# BL602 register map
Vendor: bouffalolab; Series: WiFi BT
Registers are 32-bit, read-write, reset 0x0 unless marked. A register's access mark holds for its fields unless they carry their own. Offsets are from the block's base; [hi:lo] are bit positions.

## CCI
Base 0x40008000
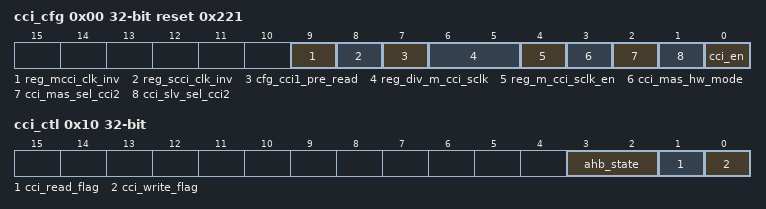
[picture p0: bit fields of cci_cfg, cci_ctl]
0x00 cci_cfg reset 0x221
  [9] reg_mcci_clk_inv, [8] reg_scci_clk_inv, [7] cfg_cci1_pre_read, [6:5] reg_div_m_cci_sclk, [4] reg_m_cci_sclk_en, [3] cci_mas_hw_mode, [2] cci_mas_sel_cci2, [1] cci_slv_sel_cci2, [0] cci_en
0x04 cci_addr
  [31:0] apb_cci_addr
0x08 cci_wdata
  [31:0] apb_cci_wdata
0x0C cci_rdata
  [31:0] apb_cci_rdata ro
0x10 cci_ctl
  [3:2] ahb_state ro, [1] cci_read_flag ro, [0] cci_write_flag ro

## L1C — Cache control
Base 0x40009000
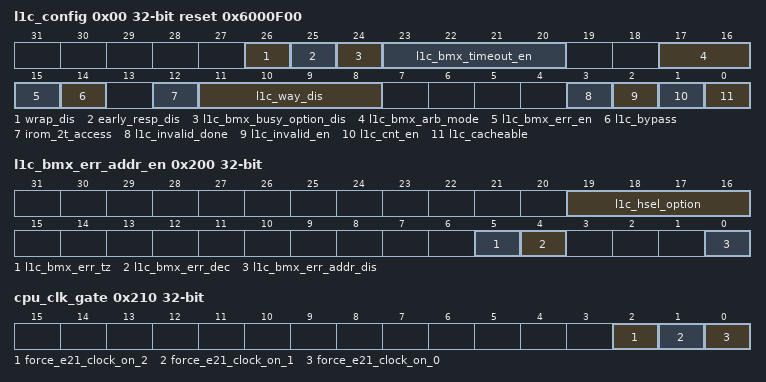
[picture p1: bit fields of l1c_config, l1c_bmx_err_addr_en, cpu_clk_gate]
0x00 l1c_config reset 0x6000F00
  [26] wrap_dis, [25] early_resp_dis, [24] l1c_bmx_busy_option_dis, [23:20] l1c_bmx_timeout_en, [17:16] l1c_bmx_arb_mode, [15] l1c_bmx_err_en, [14] l1c_bypass, [12] irom_2t_access, [11:8] l1c_way_dis, [3] l1c_invalid_done ro, [2] l1c_invalid_en, [1] l1c_cnt_en, [0] l1c_cacheable
0x04 hit_cnt_lsb ro
0x08 hit_cnt_msb ro
0x0C miss_cnt ro
0x10 l1c_range
0x200 l1c_bmx_err_addr_en
  [19:16] l1c_hsel_option, [5] l1c_bmx_err_tz ro, [4] l1c_bmx_err_dec ro, [0] l1c_bmx_err_addr_dis
0x204 l1c_bmx_err_addr ro
0x208 irom1_misr_dataout_0 ro
0x20C irom1_misr_dataout_1
0x210 cpu_clk_gate
  [2] force_e21_clock_on_2, [1] force_e21_clock_on_1, [0] force_e21_clock_on_0

## UART — UART control
Base 0x4000A000
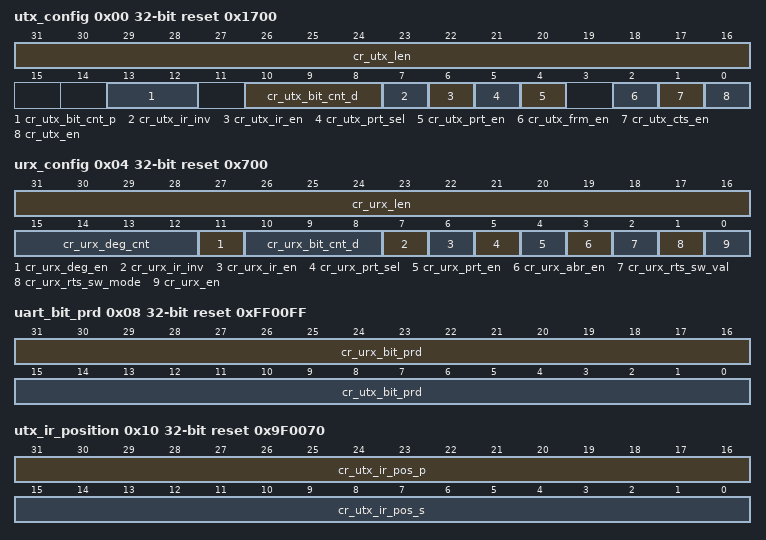
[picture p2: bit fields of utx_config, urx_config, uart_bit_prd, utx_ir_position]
0x00 utx_config reset 0x1700
  [31:16] cr_utx_len, [13:12] cr_utx_bit_cnt_p, [10:8] cr_utx_bit_cnt_d, [7] cr_utx_ir_inv, [6] cr_utx_ir_en, [5] cr_utx_prt_sel, [4] cr_utx_prt_en, [2] cr_utx_frm_en, [1] cr_utx_cts_en, [0] cr_utx_en
0x04 urx_config reset 0x700
  [31:16] cr_urx_len, [15:12] cr_urx_deg_cnt, [11] cr_urx_deg_en, [10:8] cr_urx_bit_cnt_d, [7] cr_urx_ir_inv, [6] cr_urx_ir_en, [5] cr_urx_prt_sel, [4] cr_urx_prt_en, [3] cr_urx_abr_en, [2] cr_urx_rts_sw_val, [1] cr_urx_rts_sw_mode, [0] cr_urx_en
0x08 uart_bit_prd reset 0xFF00FF
  [31:16] cr_urx_bit_prd, [15:0] cr_utx_bit_prd
0x0C data_config
  [0] cr_uart_bit_inv
0x10 utx_ir_position reset 0x9F0070
  [31:16] cr_utx_ir_pos_p, [15:0] cr_utx_ir_pos_s
0x14 urx_ir_position reset 0x6F
  [15:0] cr_urx_ir_pos_s
0x18 urx_rto_timer reset 0xF
  [7:0] cr_urx_rto_value
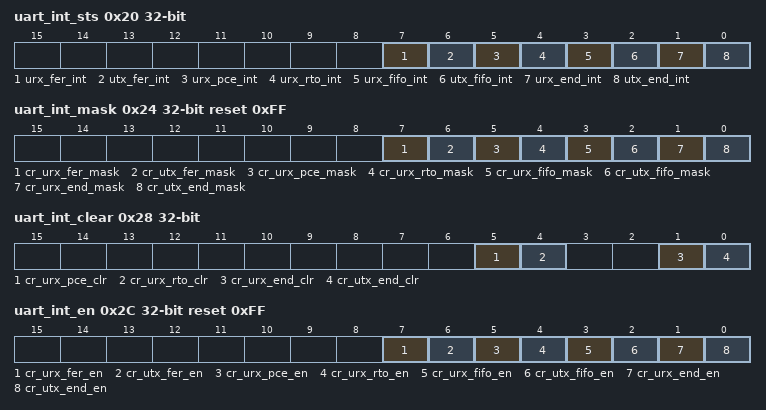
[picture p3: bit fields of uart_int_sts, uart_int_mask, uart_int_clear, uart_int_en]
0x20 uart_int_sts ro — UART interrupt status
  [7] urx_fer_int, [6] utx_fer_int, [5] urx_pce_int, [4] urx_rto_int, [3] urx_fifo_int, [2] utx_fifo_int, [1] urx_end_int, [0] utx_end_int
0x24 uart_int_mask reset 0xFF — UART interrupt mask
  [7] cr_urx_fer_mask, [6] cr_utx_fer_mask, [5] cr_urx_pce_mask, [4] cr_urx_rto_mask, [3] cr_urx_fifo_mask, [2] cr_utx_fifo_mask, [1] cr_urx_end_mask, [0] cr_utx_end_mask
0x28 uart_int_clear — UART interrupt clear
  [5] cr_urx_pce_clr, [4] cr_urx_rto_clr, [1] cr_urx_end_clr, [0] cr_utx_end_clr
0x2C uart_int_en reset 0xFF — UART interrupt enable
  [7] cr_urx_fer_en, [6] cr_utx_fer_en, [5] cr_urx_pce_en, [4] cr_urx_rto_en, [3] cr_urx_fifo_en, [2] cr_utx_fifo_en, [1] cr_urx_end_en, [0] cr_utx_end_en
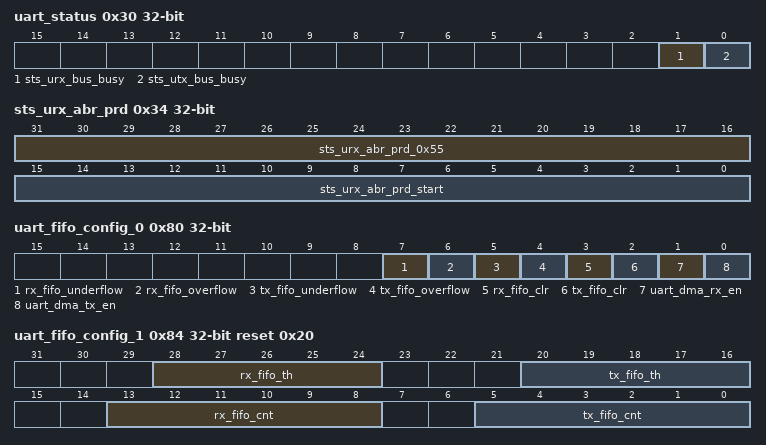
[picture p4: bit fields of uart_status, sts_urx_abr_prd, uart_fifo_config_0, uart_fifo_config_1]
0x30 uart_status ro
  [1] sts_urx_bus_busy, [0] sts_utx_bus_busy
0x34 sts_urx_abr_prd ro
  [31:16] sts_urx_abr_prd_0x55, [15:0] sts_urx_abr_prd_start
0x80 uart_fifo_config_0
  [7] rx_fifo_underflow ro, [6] rx_fifo_overflow ro, [5] tx_fifo_underflow ro, [4] tx_fifo_overflow ro, [3] rx_fifo_clr, [2] tx_fifo_clr, [1] uart_dma_rx_en, [0] uart_dma_tx_en
0x84 uart_fifo_config_1 reset 0x20
  [28:24] rx_fifo_th, [20:16] tx_fifo_th, [13:8] rx_fifo_cnt ro, [5:0] tx_fifo_cnt ro
0x88 uart_fifo_wdata wo
  [7:0] uart_fifo_wdata
0x8C uart_fifo_rdata ro
  [7:0] uart_fifo_rdata

## SPI — SPI master / slave control
Base 0x4000A200
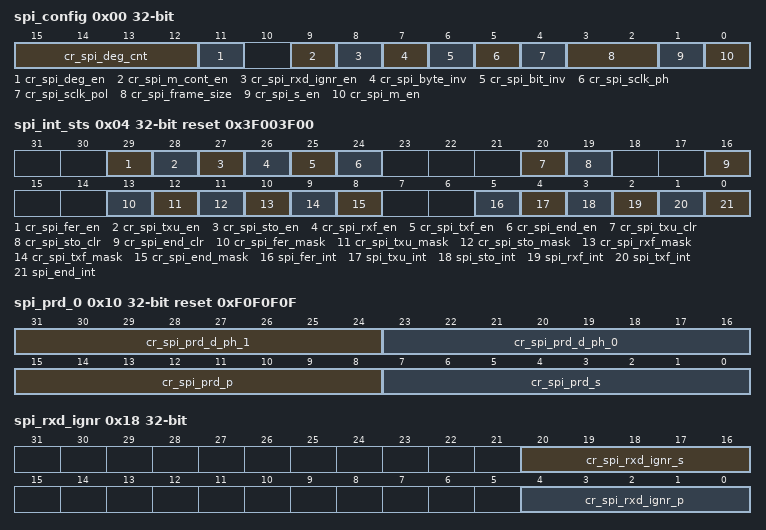
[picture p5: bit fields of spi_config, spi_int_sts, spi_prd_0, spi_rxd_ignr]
0x00 spi_config
  [15:12] cr_spi_deg_cnt, [11] cr_spi_deg_en, [9] cr_spi_m_cont_en, [8] cr_spi_rxd_ignr_en, [7] cr_spi_byte_inv, [6] cr_spi_bit_inv, [5] cr_spi_sclk_ph, [4] cr_spi_sclk_pol, [3:2] cr_spi_frame_size, [1] cr_spi_s_en, [0] cr_spi_m_en
0x04 spi_int_sts reset 0x3F003F00
  [29] cr_spi_fer_en, [28] cr_spi_txu_en, [27] cr_spi_sto_en, [26] cr_spi_rxf_en, [25] cr_spi_txf_en, [24] cr_spi_end_en, [20] cr_spi_txu_clr, [19] cr_spi_sto_clr, [16] cr_spi_end_clr, [13] cr_spi_fer_mask, [12] cr_spi_txu_mask, [11] cr_spi_sto_mask, [10] cr_spi_rxf_mask, [9] cr_spi_txf_mask, [8] cr_spi_end_mask, [5] spi_fer_int ro, [4] spi_txu_int ro, [3] spi_sto_int ro, [2] spi_rxf_int ro, [1] spi_txf_int ro, [0] spi_end_int ro
0x08 spi_bus_busy ro
  [0] sts_spi_bus_busy
0x10 spi_prd_0 reset 0xF0F0F0F
  [31:24] cr_spi_prd_d_ph_1, [23:16] cr_spi_prd_d_ph_0, [15:8] cr_spi_prd_p, [7:0] cr_spi_prd_s
0x14 spi_prd_1 reset 0xF
  [7:0] cr_spi_prd_i
0x18 spi_rxd_ignr
  [20:16] cr_spi_rxd_ignr_s, [4:0] cr_spi_rxd_ignr_p
0x1C spi_sto_value reset 0xFFF
  [11:0] cr_spi_sto_value
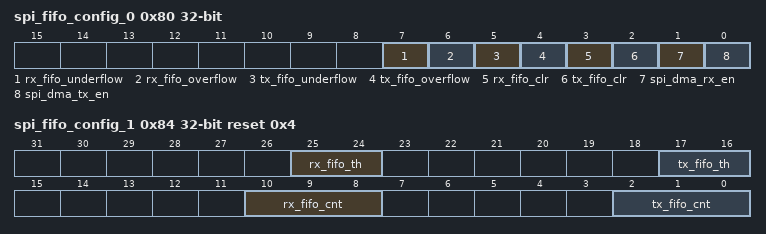
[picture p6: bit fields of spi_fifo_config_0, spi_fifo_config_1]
0x80 spi_fifo_config_0
  [7] rx_fifo_underflow ro, [6] rx_fifo_overflow ro, [5] tx_fifo_underflow ro, [4] tx_fifo_overflow ro, [3] rx_fifo_clr, [2] tx_fifo_clr, [1] spi_dma_rx_en, [0] spi_dma_tx_en
0x84 spi_fifo_config_1 reset 0x4
  [25:24] rx_fifo_th, [17:16] tx_fifo_th, [10:8] rx_fifo_cnt ro, [2:0] tx_fifo_cnt ro
0x88 spi_fifo_wdata wo
0x8C spi_fifo_rdata ro
